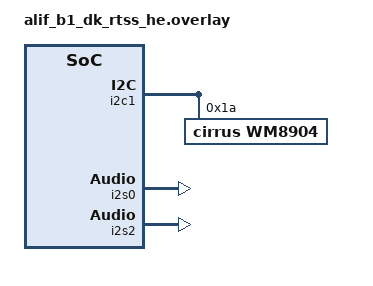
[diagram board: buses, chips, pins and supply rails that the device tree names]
/*
 * Copyright (c) 2024 Alif Semiconductor.
 * SPDX-License-Identifier: Apache-2.0
 */

#include <dt-bindings/i2c/i2c.h>

/*
 * I2S_0 => Speaker Output
 * I2S_2 => Mic Input
 */

i2s_tx: &i2s0 {
	status = "okay";
};

i2s_rx: &i2s2 {
	status = "okay";
};

&pinctrl {
	pinctrl_i2s0: pinctrl_i2s0 {
		group0 {
			// Uses different I2S0 pins for wm8904 WS and SCLK than default
			pinmux = <PINMUX_PIN(PIN_P2_4, 2)>, /* I2S0 SDI B  */
				<PINMUX_PIN(PIN_P2_5, 2)>, /* I2S0 SDO B  */
				<PINMUX_PIN(PIN_P1_7, 3)>, /* I2S0 WS A   */
				<PINMUX_PIN(PIN_P1_6, 3)>; /* I2S0 SCLK A */
		};
	};
};

/ {
	soc {
		i2c1: i2c1@49011000 {
			wm8904: wm8904@1a {
				compatible = "cirrus,wm8904";
				reg = <0x1a>;
				status = "okay";
			};
		};
	};
};
